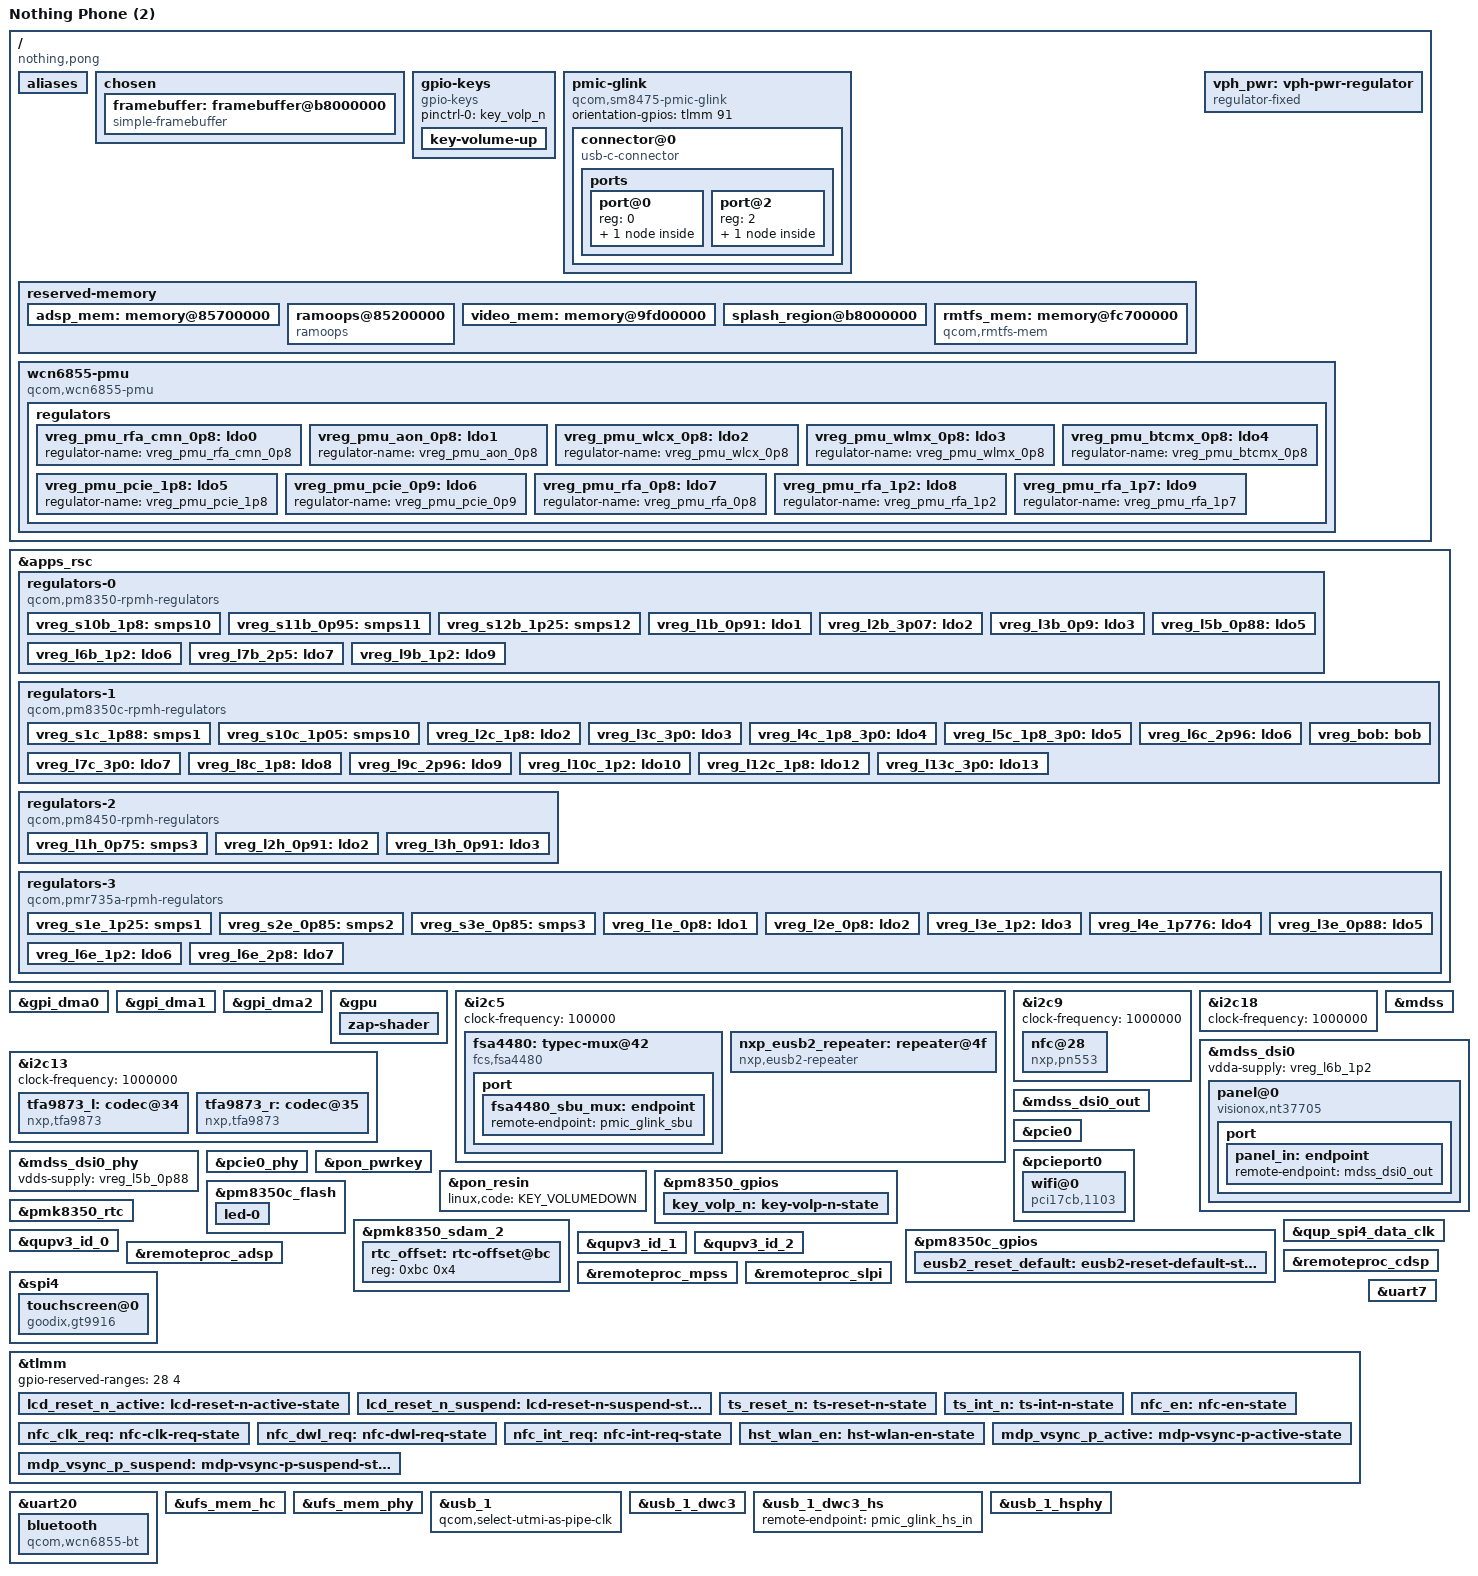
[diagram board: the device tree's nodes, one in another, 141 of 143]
// SPDX-License-Identifier: BSD-3-Clause
/*
 * Copyright (c) 2025, Danila Tikhonov <danila@jiaxyga.com>
 */
/dts-v1/;

#include <dt-bindings/leds/common.h>
#include <dt-bindings/pinctrl/qcom,pmic-gpio.h>
#include <dt-bindings/regulator/qcom,rpmh-regulator.h>

#include "sm8475.dtsi"
#include "pm8350.dtsi"
#include "pm8350b.dtsi"
#include "pm8350c.dtsi"
#include "pm8450.dtsi"
#include "pmk8350.dtsi"
#include "pmr735a.dtsi"

/delete-node/ &video_mem;
/delete-node/ &adsp_mem;
/delete-node/ &rmtfs_mem;

/ {
	model = "Nothing Phone (2)";
	compatible = "nothing,pong", "qcom,sm8475";
	chassis-type = "handset";

	aliases {
		hsuart0 = &uart20;
		serial0 = &uart7;
	};

	chosen {
		#address-cells = <2>;
		#size-cells = <2>;
		ranges;

		//bootargs = "PMOS_NOSPLASH console=tty0 clk_ignore_unused pd_ignore_unused";

		framebuffer: framebuffer@b8000000 {
			compatible = "simple-framebuffer";
			reg = <0x0 0xb8000000 0x0 0x2b00000>;
			width = <1080>;
			height = <2412>;
			stride = <(1080 * 4)>;
			format = "a8r8g8b8";

			clocks = <&gcc GCC_DISP_HF_AXI_CLK>;
		};
	};

	/* goodix,fingerprint */

	gpio-keys {
		compatible = "gpio-keys";

		pinctrl-0 = <&key_volp_n>;
		pinctrl-names = "default";

		key-volume-up {
			label = "Volume Up";
			linux,code = <KEY_VOLUMEUP>;
			gpios = <&pm8350_gpios 6 GPIO_ACTIVE_LOW>;
			debounce-interval = <15>;
			linux,can-disable;
			wakeup-source;
		};
	};

	pmic-glink {
		compatible = "qcom,sm8475-pmic-glink",
			     "qcom,sm8450-pmic-glink",
			     "qcom,pmic-glink";
		#address-cells = <1>;
		#size-cells = <0>;

		orientation-gpios = <&tlmm 91 GPIO_ACTIVE_HIGH>; // LOW?

		connector@0 {
			compatible = "usb-c-connector";
			reg = <0>;
			power-role = "dual";
			data-role = "dual";

			ports {
				#address-cells = <1>;
				#size-cells = <0>;

				port@0 {
					reg = <0>;

					pmic_glink_hs_in: endpoint {
						remote-endpoint = <&usb_1_dwc3_hs>;
					};
				};

				// USB3 not present, so no port@1

				port@2 {
					reg = <2>;

					pmic_glink_sbu: endpoint {
						remote-endpoint = <&fsa4480_sbu_mux>;
					};
				};
			};
		};
	};

	reserved-memory {
		adsp_mem: memory@85700000 {
			reg = <0x0 0x85700000 0x0 0x2800000>;
			no-map;
		};

		ramoops@85200000 {
			compatible = "ramoops";
			reg = <0x0 0x85200000 0x0 0x400000>;

			record-size = <0x200000>;
			pmsg-size = <0x200000>;
			console-size = <0x200000>;
			no-map;
		};

		video_mem: memory@9fd00000 {
			reg = <0x0 0x9fd00000 0x0 0x700000>;
			no-map;
		};

		splash_region@b8000000 {
			reg = <0x0 0xb8000000 0x0 0x2b00000>;
			no-map;
		};

		rmtfs_mem: memory@fc700000 {
			compatible = "qcom,rmtfs-mem";
			reg = <0x0 0xf3300000 0x0 0x280000>;
			no-map;

			qcom,client-id = <1>;
			qcom,vmid = <QCOM_SCM_VMID_MSS_MSA>;
		};
	};

	vph_pwr: vph-pwr-regulator {
		compatible = "regulator-fixed";
		regulator-name = "vph_pwr";
		regulator-min-microvolt = <3700000>;
		regulator-max-microvolt = <3700000>;

		regulator-always-on;
		regulator-boot-on;
	};

	wcn6855-pmu {
		compatible = "qcom,wcn6855-pmu";

		pinctrl-0 = <&hst_wlan_en>;
		pinctrl-names = "default";

		wlan-enable-gpios = <&tlmm 80 GPIO_ACTIVE_HIGH>;
		bt-enable-gpios = <&tlmm 81 GPIO_ACTIVE_HIGH>;

		vddio-supply = <&vreg_s10b_1p8>;
		vddaon-supply = <&vreg_s2e_0p85>;
		vddpmu-supply = <&vreg_s11b_0p95>;
		vddrfa0p95-supply = <&vreg_s11b_0p95>;
		vddrfa1p3-supply = <&vreg_s12b_1p25>;
		vddrfa1p9-supply = <&vreg_s1c_1p88>;
		vddpcie1p3-supply = <&vreg_s12b_1p25>;
		vddpcie1p9-supply = <&vreg_s1c_1p88>;

		regulators {
			vreg_pmu_rfa_cmn_0p8: ldo0 {
				regulator-name = "vreg_pmu_rfa_cmn_0p8";
			};

			vreg_pmu_aon_0p8: ldo1 {
				regulator-name = "vreg_pmu_aon_0p8";
			};

			vreg_pmu_wlcx_0p8: ldo2 {
				regulator-name = "vreg_pmu_wlcx_0p8";
			};

			vreg_pmu_wlmx_0p8: ldo3 {
				regulator-name = "vreg_pmu_wlmx_0p8";
			};

			vreg_pmu_btcmx_0p8: ldo4 {
				regulator-name = "vreg_pmu_btcmx_0p8";
			};

			vreg_pmu_pcie_1p8: ldo5 {
				regulator-name = "vreg_pmu_pcie_1p8";
			};

			vreg_pmu_pcie_0p9: ldo6 {
				regulator-name = "vreg_pmu_pcie_0p9";
			};

			vreg_pmu_rfa_0p8: ldo7 {
				regulator-name = "vreg_pmu_rfa_0p8";
			};

			vreg_pmu_rfa_1p2: ldo8 {
				regulator-name = "vreg_pmu_rfa_1p2";
			};

			vreg_pmu_rfa_1p7: ldo9 {
				regulator-name = "vreg_pmu_rfa_1p7";
			};
		};
	};
};

&apps_rsc {
	regulators-0 {
		compatible = "qcom,pm8350-rpmh-regulators";
		qcom,pmic-id = "b";

		vdd-s1-supply = <&vph_pwr>;
		vdd-s2-supply = <&vph_pwr>;
		vdd-s3-supply = <&vph_pwr>;
		vdd-s4-supply = <&vph_pwr>;
		vdd-s5-supply = <&vph_pwr>;
		vdd-s6-supply = <&vph_pwr>;
		vdd-s7-supply = <&vph_pwr>;
		vdd-s8-supply = <&vph_pwr>;
		vdd-s9-supply = <&vph_pwr>;
		vdd-s10-supply = <&vph_pwr>;
		vdd-s11-supply = <&vph_pwr>;
		vdd-s12-supply = <&vph_pwr>;

		vdd-l1-l4-supply = <&vreg_s11b_0p95>;
		vdd-l2-l7-supply = <&vreg_bob>;
		vdd-l3-l5-supply = <&vreg_s11b_0p95>;
		vdd-l6-l9-l10-supply = <&vreg_s12b_1p25>;

		/*
		 * ARC regulators:
		 * s5 - gfx.lvl
		 * l8 - lcx.lvl
		 */

		vreg_s10b_1p8: smps10 {
			regulator-name = "vreg_s10b_1p8";
			regulator-min-microvolt = <1800000>;
			regulator-max-microvolt = <1800000>;
		};

		vreg_s11b_0p95: smps11 {
			regulator-name = "vreg_s11b_0p95";
			regulator-min-microvolt = <382000>;
			regulator-max-microvolt = <1170000>;
		};

		vreg_s12b_1p25: smps12 {
			regulator-name = "vreg_s12b_1p25";
			regulator-min-microvolt = <1224000>;
			regulator-max-microvolt = <2040000>;
		};

		vreg_l1b_0p91: ldo1 {
			regulator-name = "vreg_l1b_0p91";
			regulator-min-microvolt = <830000>;
			regulator-max-microvolt = <920000>;
			regulator-initial-mode = <RPMH_REGULATOR_MODE_HPM>;
		};

		vreg_l2b_3p07: ldo2 {
			regulator-name = "vreg_l2b_3p07";
			regulator-min-microvolt = <2700000>;
			regulator-max-microvolt = <3300000>;
			regulator-initial-mode = <RPMH_REGULATOR_MODE_HPM>;
		};

		vreg_l3b_0p9: ldo3 {
			regulator-name = "vreg_l3b_0p9";
			regulator-min-microvolt = <870000>;
			regulator-max-microvolt = <970000>;
			regulator-initial-mode = <RPMH_REGULATOR_MODE_HPM>;
		};

		vreg_l5b_0p88: ldo5 {
			regulator-name = "vreg_l5b_0p88";
			regulator-min-microvolt = <720000>;
			regulator-max-microvolt = <958000>;
			regulator-initial-mode = <RPMH_REGULATOR_MODE_HPM>;
		};

		vreg_l6b_1p2: ldo6 {
			regulator-name = "vreg_l6b_1p2";
			regulator-min-microvolt = <1200000>;
			regulator-max-microvolt = <1216000>;
			regulator-initial-mode = <RPMH_REGULATOR_MODE_HPM>;
		};

		vreg_l7b_2p5: ldo7 {
			regulator-name = "vreg_l7b_2p5";
			regulator-min-microvolt = <2400000>;
			regulator-max-microvolt = <3544000>;
			regulator-initial-mode = <RPMH_REGULATOR_MODE_HPM>;
		};

		vreg_l9b_1p2: ldo9 {
			regulator-name = "vreg_l9b_1p2";
			regulator-min-microvolt = <1200000>;
			regulator-max-microvolt = <1304000>;
			regulator-initial-mode = <RPMH_REGULATOR_MODE_HPM>;
		};
	};

	regulators-1 {
		compatible = "qcom,pm8350c-rpmh-regulators";
		qcom,pmic-id = "c";

		vdd-s1-supply = <&vph_pwr>;
		vdd-s2-supply = <&vph_pwr>;
		vdd-s3-supply = <&vph_pwr>;
		vdd-s4-supply = <&vph_pwr>;
		vdd-s5-supply = <&vph_pwr>;
		vdd-s6-supply = <&vph_pwr>;
		vdd-s7-supply = <&vph_pwr>;
		vdd-s8-supply = <&vph_pwr>;
		vdd-s9-supply = <&vph_pwr>;
		vdd-s10-supply = <&vph_pwr>;

		vdd-l1-l12-supply = <&vreg_s1c_1p88>;
		vdd-l2-l8-supply = <&vreg_s1c_1p88>;
		vdd-l3-l4-l5-l7-l13-supply = <&vreg_bob>;
		vdd-l6-l9-l11-supply = <&vreg_bob>;
		vdd-l10-supply = <&vreg_s12b_1p25>;

		vdd-bob-supply = <&vph_pwr>;

		/*
		 * ARC regulators:
		 * s2 - mxc.lvl
		 * s4 - mss.lvl
		 * s6 - cx.lvl
		 */

		vreg_s1c_1p88: smps1 {
			regulator-name = "vreg_s1c_1p88";
			regulator-min-microvolt = <1900000>;
			regulator-max-microvolt = <2024000>;
		};

		vreg_s10c_1p05: smps10 {
			regulator-name = "vreg_s10c_1p05";
			regulator-min-microvolt = <1052000>;
			regulator-max-microvolt = <1170000>;
		};

		vreg_l2c_1p8: ldo2 {
			regulator-name = "vreg_l2c_1p8";
			regulator-min-microvolt = <1800000>;
			regulator-max-microvolt = <1980000>;
			regulator-initial-mode = <RPMH_REGULATOR_MODE_HPM>;
		};

		vreg_l3c_3p0: ldo3 {
			regulator-name = "vreg_l3c_3p0";
			regulator-min-microvolt = <2700000>;
			regulator-max-microvolt = <3544000>;
			regulator-initial-mode = <RPMH_REGULATOR_MODE_HPM>;
		};

		vreg_l4c_1p8_3p0: ldo4 {
			regulator-name = "vreg_l4c_1p8_3p0";
			regulator-min-microvolt = <1620000>;
			regulator-max-microvolt = <3300000>;
			regulator-initial-mode = <RPMH_REGULATOR_MODE_HPM>;
		};

		vreg_l5c_1p8_3p0: ldo5 {
			regulator-name = "vreg_l5c_1p8_3p0";
			regulator-min-microvolt = <1620000>;
			regulator-max-microvolt = <3300000>;
			regulator-initial-mode = <RPMH_REGULATOR_MODE_HPM>;
		};

		vreg_l6c_2p96: ldo6 {
			regulator-name = "vreg_l6c_2p96";
			regulator-min-microvolt = <1800000>;
			regulator-max-microvolt = <3544000>;
			regulator-initial-mode = <RPMH_REGULATOR_MODE_HPM>;
		};

		vreg_l7c_3p0: ldo7 {
			regulator-name = "vreg_l7c_3p0";
			regulator-min-microvolt = <3000000>;
			regulator-max-microvolt = <3544000>;
			regulator-initial-mode = <RPMH_REGULATOR_MODE_HPM>;
		};

		vreg_l8c_1p8: ldo8 {
			regulator-name = "vreg_l8c_1p8";
			regulator-min-microvolt = <1800000>;
			regulator-max-microvolt = <2000000>;
			regulator-initial-mode = <RPMH_REGULATOR_MODE_HPM>;
		};

		vreg_l9c_2p96: ldo9 {
			regulator-name = "vreg_l9c_2p96";
			regulator-min-microvolt = <2700000>;
			regulator-max-microvolt = <3544000>;
			regulator-initial-mode = <RPMH_REGULATOR_MODE_HPM>;
		};

		vreg_l10c_1p2: ldo10 {
			regulator-name = "vreg_l10c_1p2";
			regulator-min-microvolt = <1200000>;
			regulator-max-microvolt = <1304000>;
			regulator-initial-mode = <RPMH_REGULATOR_MODE_HPM>;
		};

		vreg_l12c_1p8: ldo12 {
			regulator-name = "vreg_l12c_1p8";
			regulator-min-microvolt = <1800000>;
			regulator-max-microvolt = <1980000>;
			regulator-initial-mode = <RPMH_REGULATOR_MODE_HPM>;
		};

		vreg_l13c_3p0: ldo13 {
			regulator-name = "vreg_l13c_3p0";
			regulator-min-microvolt = <2700000>;
			regulator-max-microvolt = <3544000>;
			regulator-initial-mode = <RPMH_REGULATOR_MODE_HPM>;
		};

		vreg_bob: bob {
			regulator-name = "vreg_bob";
			regulator-min-microvolt = <3008000>;
			regulator-max-microvolt = <3960000>;
			regulator-initial-mode = <RPMH_REGULATOR_MODE_AUTO>;
		};
	};

	regulators-2 {
		compatible = "qcom,pm8450-rpmh-regulators";
		qcom,pmic-id = "h";

		vdd-s1-supply = <&vph_pwr>;
		vdd-s2-supply = <&vph_pwr>;
		vdd-s3-supply = <&vph_pwr>;
		vdd-s4-supply = <&vph_pwr>;
		vdd-s5-supply = <&vph_pwr>;
		vdd-s6-supply = <&vph_pwr>;

		vdd-l2-supply = <&vreg_bob>;
		vdd-l3-supply = <&vreg_bob>;
		vdd-l4-supply = <&vreg_bob>;

		/*
		 * ARC regulators:
		 * S2 - ebi.lvl
		 * S4 - mmcx.lvl
		 * S6 - mx.lvl
		 * L1 - lmx.lvl
		 */

		vreg_l1h_0p75: smps3 {
			regulator-name = "vreg_l1h_0p75";
			regulator-min-microvolt = <470000>;
			regulator-max-microvolt = <570000>;
		};

		vreg_l2h_0p91: ldo2 {
			regulator-name = "vreg_l2h_0p91";
			regulator-min-microvolt = <820000>;
			regulator-max-microvolt = <958000>;
			regulator-initial-mode = <RPMH_REGULATOR_MODE_HPM>;
		};

		vreg_l3h_0p91: ldo3 {
			regulator-name = "vreg_l3h_0p91";
			regulator-min-microvolt = <866000>;
			regulator-max-microvolt = <958000>;
			regulator-initial-mode = <RPMH_REGULATOR_MODE_HPM>;
		};
	};

	regulators-3 {
		compatible = "qcom,pmr735a-rpmh-regulators";
		qcom,pmic-id = "e";

		vdd-s1-supply = <&vph_pwr>;
		vdd-s2-supply = <&vph_pwr>;
		vdd-s3-supply = <&vph_pwr>;

		vdd-l1-l2-supply = <&vreg_s2e_0p85>;
		vdd-l3-supply = <&vreg_s1e_1p25>;
		vdd-l4-supply = <&vreg_s1c_1p88>;
		vdd-l5-l6-supply = <&vreg_s1c_1p88>;
		vdd-l7-bob-supply = <&vreg_bob>;

		vreg_s1e_1p25: smps1 {
			regulator-name = "vreg_s1e_1p25";
			regulator-min-microvolt = <1200000>;
			regulator-max-microvolt = <1296000>;
		};

		vreg_s2e_0p85: smps2 {
			regulator-name = "vreg_s2e_0p85";
			regulator-min-microvolt = <500000>;
			regulator-max-microvolt = <1040000>;
		};

		vreg_s3e_0p85: smps3 { // FIXME!
			regulator-name = "vreg_s3e_0p85";
			regulator-min-microvolt = <300000>;
			regulator-max-microvolt = <2352000>;
		};

		vreg_l1e_0p8: ldo1 {
			regulator-name = "vreg_l1e_0p8";
			regulator-min-microvolt = <800000>;
			regulator-max-microvolt = <880000>;
		};

		vreg_l2e_0p8: ldo2 {
			regulator-name = "vreg_l2e_0p8";
			regulator-min-microvolt = <480000>;
			regulator-max-microvolt = <1200000>;
		};

		vreg_l3e_1p2: ldo3 {
			regulator-name = "vreg_l3e_1p2";
			regulator-min-microvolt = <1200000>;
			regulator-max-microvolt = <1200000>;
		};

		vreg_l4e_1p776: ldo4 {
			regulator-name = "vreg_l4e_1p776";
			regulator-min-microvolt = <1776000>;
			regulator-max-microvolt = <1776000>;
		};

		vreg_l3e_0p88: ldo5 {
			regulator-name = "vreg_l3e_0p88";
			regulator-min-microvolt = <880000>;
			regulator-max-microvolt = <920000>;
		};

		vreg_l6e_1p2: ldo6 {
			regulator-name = "vreg_l6e_1p2";
			regulator-min-microvolt = <1200000>;
			regulator-max-microvolt = <1200000>;
		};

		vreg_l6e_2p8: ldo7 {
			regulator-name = "vreg_l6e_2p8";
			regulator-min-microvolt = <2800000>;
			regulator-max-microvolt = <2800000>;
		};
	};
};

&gpi_dma0 {
	status = "okay";
};

&gpi_dma1 {
	status = "okay";
};

&gpi_dma2 {
	status = "okay";
};

&gpu {
	status = "okay";

	zap-shader {
		firmware-name = "qcom/sm8475/nothing/pong/a730_zap.mbn";
	};
};

&i2c5 {
	clock-frequency = <100000>;
	status = "okay";

	/* nq@64 rtc6226 */

	fsa4480: typec-mux@42 {
		compatible = "fcs,fsa4480";
		reg = <0x42>;

		vcc-supply = <&vreg_bob>;
		mode-switch;
		orientation-switch;

		port {
			fsa4480_sbu_mux: endpoint {
				remote-endpoint = <&pmic_glink_sbu>;
			};
		};
	};

	/* redriver@1c onnn,redriver */
	/* aw20036_led@3a awinic,aw20036_led */

	nxp_eusb2_repeater: repeater@4f {
		compatible = "nxp,eusb2-repeater";
		reg = <0x4f>;

		vdd18-supply = <&vreg_s10b_1p8>;
		vdd3-supply = <&vreg_l2b_3p07>;

		reset-gpio = <&pm8350c_gpios 7 GPIO_ACTIVE_HIGH>;
		pinctrl-names = "default";
		pinctrl-0 = <&eusb2_reset_default>;

		qcom,param-override-seq = <64 6 34 7 100 8>;
		/*
		 * Rx squelch detection threshold to 110mV (default is 125mV);
		 * Tx Deemphasis to 2dB, Tx Deemphasis bit duration to 0.8UI
		 * (default is 0 for both);
		 * Output Voltage Swing to 550mV (default is 450mV);
		 */
		#phy-cells = <0>;
	};
};

&i2c9 {
	clock-frequency = <1000000>;
	status = "okay";

	nfc@28 {
		compatible = "nxp,pn553",
			     "nxp,nxp-nci-i2c";
		reg = <0x28>;

		interrupt-parent = <&tlmm>;
		interrupts = <46 IRQ_TYPE_EDGE_RISING>;

		enable-gpios = <&tlmm 34 GPIO_ACTIVE_HIGH>;
		firmware-gpios = <&tlmm 45 GPIO_ACTIVE_HIGH>;

		pinctrl-0 = <&nfc_en>,
			    <&nfc_clk_req>,
			    <&nfc_dwl_req>,
			    <&nfc_int_req>;
		pinctrl-names = "default";
	};
};

&i2c13 {
	clock-frequency = <1000000>;
	status = "okay";

	tfa9873_l: codec@34 { /* EAR */
		compatible = "nxp,tfa9873",
			     "nxp,tfa9872";
		reg = <0x34>;
		reset-gpio = <&tlmm 1 GPIO_ACTIVE_HIGH>;
		#sound-dai-cells = <1>;
	};

	tfa9873_r: codec@35 { /* SPK */
		compatible = "nxp,tfa9873",
			     "nxp,tfa9872";
		reg = <0x35>;
		reset-gpio = <&tlmm 89 GPIO_ACTIVE_HIGH>;
		#sound-dai-cells = <1>;
	};
};

&i2c18 {
	clock-frequency = <1000000>;
	status = "okay";

	/* haptic_hv@5a awinic,aw8692x */
};

&mdss {
	status = "okay";
};

&mdss_dsi0 {
	vdda-supply = <&vreg_l6b_1p2>;
	status = "okay";

	panel@0 {
		compatible = "visionox,nt37705";
		reg = <0>;

		reset-gpios = <&tlmm 0 GPIO_ACTIVE_LOW>;

		vdd-supply = <&vreg_l13c_3p0>;
		vddio-supply = <&vreg_l12c_1p8>;

		pinctrl-0 = <&lcd_reset_n_active>,
			    <&mdp_vsync_p_active>;
		pinctrl-1 = <&lcd_reset_n_suspend>,
			    <&mdp_vsync_p_suspend>;
		pinctrl-names = "default", "sleep";

		port {
			panel_in: endpoint {
				remote-endpoint = <&mdss_dsi0_out>;
			};
		};
	};
};

&mdss_dsi0_out {
	remote-endpoint = <&panel_in>;
	data-lanes = <0 1 2 3>;
};

&mdss_dsi0_phy {
	vdds-supply = <&vreg_l5b_0p88>;
	status = "okay";
};

&pcie0 {
	status = "okay";
};

&pcieport0 {
	wifi@0 {
		compatible = "pci17cb,1103";
		reg = <0x10000 0x0 0x0 0x0 0x0>;

		vddrfacmn-supply = <&vreg_pmu_rfa_cmn_0p8>;
		vddaon-supply = <&vreg_pmu_aon_0p8>;
		vddwlcx-supply = <&vreg_pmu_wlcx_0p8>;
		vddwlmx-supply = <&vreg_pmu_wlmx_0p8>;
		vddpcie1p8-supply = <&vreg_pmu_pcie_1p8>;
		vddpcie0p9-supply = <&vreg_pmu_pcie_0p9>;
		vddrfa0p8-supply = <&vreg_pmu_rfa_0p8>;
		vddrfa1p2-supply = <&vreg_pmu_rfa_1p2>;
		vddrfa1p8-supply = <&vreg_pmu_rfa_1p7>;
	};
};

&pcie0_phy {
	vdda-phy-supply = <&vreg_l5b_0p88>;
	vdda-pll-supply = <&vreg_l10c_1p2>;
	status = "okay";
};

&pon_pwrkey {
	status = "okay";
};

&pon_resin {
	linux,code = <KEY_VOLUMEDOWN>;

	status = "okay";
};

&pm8350_gpios {
	key_volp_n: key-volp-n-state {
		pins = "gpio6";
		function = PMIC_GPIO_FUNC_NORMAL;
		bias-pull-up;
		input-enable;
		power-source = <1>;
	};
};

&pm8350c_flash {
	status = "okay";

	led-0 {
		function = LED_FUNCTION_FLASH;
		color = <LED_COLOR_ID_YELLOW>;
		led-sources = <1>, <4>;
		led-max-microamp = <500000>;
		flash-max-microamp = <1500000>;
		flash-max-timeout-us = <1280000>;
	};
};

&pm8350c_gpios {
	eusb2_reset_default: eusb2-reset-default-state {
		pins = "gpio7";
		function = PMIC_GPIO_FUNC_NORMAL;
		input-enable;
		output-enable;
		bias-disable;
		power-source = <1>;	/* 1.8V */
		qcom,drive-strength = <PMIC_GPIO_STRENGTH_MED>;
	};
};

&pmk8350_rtc {
	nvmem-cells = <&rtc_offset>;
	nvmem-cell-names = "offset";

	status = "okay";
};

&pmk8350_sdam_2 {
	status = "okay";

	rtc_offset: rtc-offset@bc {
		reg = <0xbc 0x4>;
	};
};

&qup_spi4_data_clk {
	drive-strength = <6>;
	bias-disable;
};

&qupv3_id_0 {
	status = "okay";
};

&qupv3_id_1 {
	status = "okay";
};

&qupv3_id_2 {
	status = "okay";
};

&remoteproc_adsp {
	firmware-name = "qcom/sm8475/nothing/pong/adsp.mbn";
	status = "okay";
};

&remoteproc_cdsp {
	firmware-name = "qcom/sm8475/nothing/pong/cdsp.mbn";
	status = "okay";
};

&remoteproc_mpss {
	firmware-name = "qcom/sm8475/nothing/pong/modem.mbn";
	status = "okay";
};

&remoteproc_slpi {
	firmware-name = "qcom/sm8475/nothing/pong/slpi.mbn";
	status = "okay";
};

&spi4 {
	status = "okay";

	touchscreen@0 {
		compatible = "goodix,gt9916";
		reg = <0>;

		interrupt-parent = <&tlmm>;
		interrupts = <21 0x2008>;

		reset-gpios = <&tlmm 20 GPIO_ACTIVE_LOW>;

		avdd-supply = <&vreg_l3c_3p0>;
		vddio-supply = <&vreg_l12c_1p8>;

		spi-max-frequency = <20000000>;

		touchscreen-size-x = <1080>;
		touchscreen-size-y = <2412>;

		pinctrl-names = "default";
		pinctrl-0 = <&ts_int_n>,
			    <&ts_reset_n>;
	};
};

&tlmm {
	/* Reserved I/Os for FP */
	gpio-reserved-ranges = <28 4>;

	lcd_reset_n_active: lcd-reset-n-active-state {
		pins = "gpio0";
		function = "gpio";
		drive-strength = <8>;
		bias-disable;
	};

	lcd_reset_n_suspend: lcd-reset-n-suspend-state {
		pins = "gpio0";
		function = "gpio";
		drive-strength = <2>;
		bias-pull-down;
	};

	ts_reset_n: ts-reset-n-state {
		pins = "gpio20";
		function = "gpio";
		drive-strength = <8>;
		bias-pull-up;
	};

	ts_int_n: ts-int-n-state {
		pins = "gpio21";
		function = "gpio";
		drive-strength = <8>;
		bias-pull-up;
	};

	nfc_en: nfc-en-state {
		pins = "gpio34";
		function = "gpio";
		drive-strength = <2>;
		bias-disable;
	};

	nfc_clk_req: nfc-clk-req-state {
		pins = "gpio35";
		function = "gpio";
		drive-strength = <2>;
		bias-disable;
	};

	nfc_dwl_req: nfc-dwl-req-state {
		pins = "gpio45";
		function = "gpio";
		drive-strength = <2>;
		bias-disable;
	};

	nfc_int_req: nfc-int-req-state {
		pins = "gpio46";
		function = "gpio";
		drive-strength = <2>;
		bias-pull-down;
	};

	hst_wlan_en: hst-wlan-en-state {
		pins = "gpio80";
		function = "gpio";
		drive-strength = <10>;
		bias-pull-up;
		output-high;
	};

	mdp_vsync_p_active: mdp-vsync-p-active-state {
		pins = "gpio86";
		function = "mdp_vsync";
		drive-strength = <2>;
		bias-pull-down;
	};

	mdp_vsync_p_suspend: mdp-vsync-p-suspend-state {
		pins = "gpio86";
		function = "mdp_vsync";
		drive-strength = <2>;
		bias-pull-down;
	};
};

&uart7 {
	status = "okay";
};

&uart20 {
	status = "okay";

	bluetooth {
		compatible = "qcom,wcn6855-bt";

		vddrfacmn-supply = <&vreg_pmu_rfa_cmn_0p8>;
		vddaon-supply = <&vreg_pmu_aon_0p8>;
		vddwlcx-supply = <&vreg_pmu_wlcx_0p8>;
		vddwlmx-supply = <&vreg_pmu_wlmx_0p8>;
		vddbtcmx-supply = <&vreg_pmu_btcmx_0p8>;
		vddrfa0p8-supply = <&vreg_pmu_rfa_0p8>;
		vddrfa1p2-supply = <&vreg_pmu_rfa_1p2>;
		vddrfa1p8-supply = <&vreg_pmu_rfa_1p7>;

		max-speed = <3200000>;
	};
};

&ufs_mem_hc {
	reset-gpios = <&tlmm 210 GPIO_ACTIVE_LOW>;

	vcc-supply = <&vreg_l7b_2p5>;
	vcc-max-microamp = <1100000>;
	vccq-supply = <&vreg_l9b_1p2>;
	vccq-max-microamp = <1200000>;

	status = "okay";
};

&ufs_mem_phy {
	vdda-phy-supply = <&vreg_l5b_0p88>;
	vdda-pll-supply = <&vreg_l10c_1p2>;

	status = "okay";
};

&usb_1 {
	/* USB 2.0 only */
	qcom,select-utmi-as-pipe-clk;
	status = "okay";
};

&usb_1_dwc3 {
	dr_mode = "otg";
	maximum-speed = "high-speed";
	/* Remove USB3 phy */
	phys = <&usb_1_hsphy>;
	phy-names = "usb2-phy";
};

&usb_1_dwc3_hs {
	remote-endpoint = <&pmic_glink_hs_in>;
};

&usb_1_hsphy {
	vdd-supply = <&vreg_l5b_0p88>;
	vdda12-supply = <&vreg_l10c_1p2>;

	phys = <&nxp_eusb2_repeater>;

	status = "okay";
};
